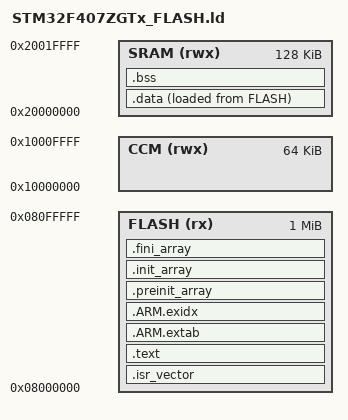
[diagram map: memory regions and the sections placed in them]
MEMORY
{
    FLASH  (rx) : ORIGIN = 0x08000000, LENGTH = 1024K
    SRAM  (rwx) : ORIGIN = 0x20000000, LENGTH = 128K
    CCM   (rwx) : ORIGIN = 0x10000000, LENGTH = 64K
}

_estack = ORIGIN(SRAM) + LENGTH(SRAM);

SECTIONS
{
    .isr_vector : { KEEP(*(.isr_vector)) . = ALIGN(4); } > FLASH

    .text : {
        . = ALIGN(4);
        *(.text) *(.text*) *(.rodata) *(.rodata*)
        *(.glue_7) *(.glue_7t)
        KEEP(*(.init)) KEEP(*(.fini))
        . = ALIGN(4);
        _etext = .;
    } > FLASH

    .ARM.extab : { *(.ARM.extab* .gnu.linkonce.armextab.*) } > FLASH
    .ARM.exidx : { *(.ARM.exidx* .gnu.linkonce.armexidx.*) } > FLASH

    .preinit_array : {
        PROVIDE_HIDDEN(__preinit_array_start = .);
        KEEP(*(.preinit_array*))
        PROVIDE_HIDDEN(__preinit_array_end = .);
    } > FLASH

    .init_array : {
        PROVIDE_HIDDEN(__init_array_start = .);
        KEEP(*(SORT(.init_array.*)))
        KEEP(*(.init_array*))
        PROVIDE_HIDDEN(__init_array_end = .);
    } > FLASH

    .fini_array : {
        PROVIDE_HIDDEN(__fini_array_start = .);
        KEEP(*(.fini_array*))
        KEEP(*(SORT(.fini_array.*)))
        PROVIDE_HIDDEN(__fini_array_end = .);
    } > FLASH

    _sidata = LOADADDR(.data);

    .data : {
        . = ALIGN(4);
        _sdata = .;
        *(.data) *(.data*)
        . = ALIGN(4);
        _edata = .;
    } > SRAM AT > FLASH

    .bss : {
        . = ALIGN(4);
        _sbss = .;
        *(.bss) *(.bss*) *(COMMON)
        . = ALIGN(4);
        _ebss = .;
    } > SRAM
}
